VERSION ""

NS_ :

BS_:

BU_: K182_PACM K43_PSCM K17_EBCM NEO K124_ASCM XXX

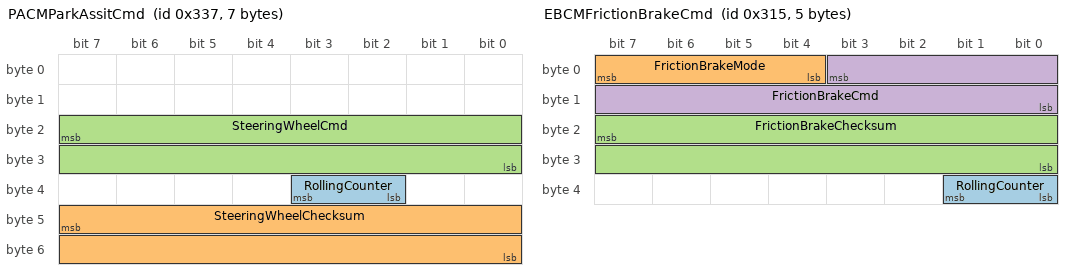
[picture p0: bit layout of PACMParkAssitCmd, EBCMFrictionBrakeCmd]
BO_ 823 PACMParkAssitCmd: 7 NEO
 SG_ RollingCounter : 35|2@0+ (1,0) [0|0] "" NEO
 SG_ SteeringWheelChecksum : 47|16@0+ (1,0) [0|0] "" NEO
 SG_ SteeringWheelCmd : 23|16@0+ (1,0) [0|0] "" NEO

BO_ 560 EBCMRegen: 6 K17_EBCM
 SG_ Regen : 1|10@0+ (1,0) [0|0] "" NEO

BO_ 368 EBCMFrictionBrakeStatus: 8 K17_EBCM
 SG_ FrictionBrakePressure : 23|16@0+ (1,0) [0|0] "" NEO
 SG_ NEW_SIGNAL_1 : 35|12@0- (1,0) [0|1] "" XXX

BO_ 789 EBCMFrictionBrakeCmd: 5 K17_EBCM
 SG_ RollingCounter : 33|2@0+ (1,0) [0|0] "" NEO
 SG_ FrictionBrakeMode : 7|4@0+ (1,0) [0|0] "" NEO
 SG_ FrictionBrakeChecksum : 23|16@0+ (1,0) [0|0] "" NEO
 SG_ FrictionBrakeCmd : 3|12@0- (1,0) [0|0] "" NEO

BO_ 192 NEW_MSG_1: 8 XXX
 SG_ NEW_SIGNAL_1 : 15|18@0- (1,0) [0|1] "" XXX

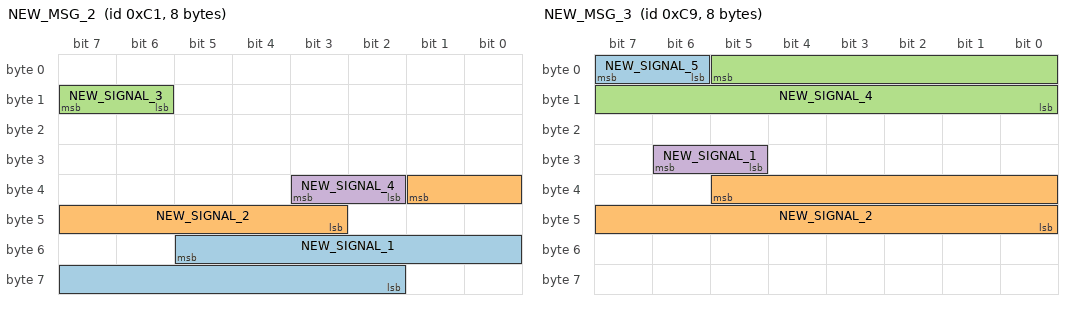
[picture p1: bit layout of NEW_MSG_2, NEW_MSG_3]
BO_ 193 NEW_MSG_2: 8 XXX
 SG_ NEW_SIGNAL_1 : 53|12@0+ (1,0) [0|1] "" XXX
 SG_ NEW_SIGNAL_2 : 33|7@0+ (1,0) [0|1] "" XXX
 SG_ NEW_SIGNAL_3 : 15|2@0+ (1,0) [0|7] "" XXX
 SG_ NEW_SIGNAL_4 : 35|2@0- (1,0) [0|1] "" XXX

BO_ 201 NEW_MSG_3: 8 XXX
 SG_ NEW_SIGNAL_5 : 7|2@0+ (1,0) [0|1] "" XXX
 SG_ NEW_SIGNAL_2 : 37|14@0+ (0.01,0) [0|16383] "" XXX
 SG_ NEW_SIGNAL_4 : 5|14@0+ (1,0) [0|1] "" XXX
 SG_ NEW_SIGNAL_1 : 30|2@0+ (1,0) [0|1] "" XXX

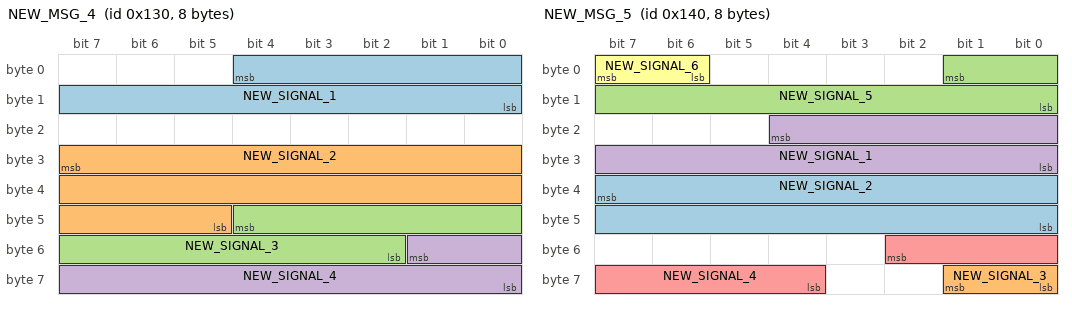
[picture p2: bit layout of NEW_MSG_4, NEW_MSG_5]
BO_ 304 NEW_MSG_4: 8 XXX
 SG_ NEW_SIGNAL_1 : 4|13@0- (1,0) [0|1] "" XXX
 SG_ NEW_SIGNAL_2 : 31|19@0- (1,0) [0|1] "" XXX
 SG_ NEW_SIGNAL_3 : 44|11@0- (1,0) [0|1] "" XXX
 SG_ NEW_SIGNAL_4 : 49|10@0- (1,0) [0|1] "" XXX

BO_ 320 NEW_MSG_5: 8 XXX
 SG_ NEW_SIGNAL_2 : 39|16@0+ (1,0) [0|1] "" XXX
 SG_ NEW_SIGNAL_3 : 57|2@0+ (1,0) [0|1] "" XXX
 SG_ NEW_SIGNAL_5 : 1|10@0- (1,0) [0|1] "" XXX
 SG_ NEW_SIGNAL_1 : 20|13@0- (1,0) [0|31] "" XXX
 SG_ NEW_SIGNAL_4 : 50|7@0+ (1,0) [0|1] "" XXX
 SG_ NEW_SIGNAL_6 : 7|2@0+ (1,0) [0|1] "" XXX

BO_ 460 NEW_MSG_6: 8 XXX
 SG_ NEW_SIGNAL_1 : 14|7@0+ (1,0) [0|1] "" XXX

BO_ 462 NEW_MSG_7: 8 XXX
 SG_ NEW_SIGNAL_1 : 4|2@0+ (1,0) [0|1] "" XXX

BO_ 381 NEW_MSG_8: 8 XXX
 SG_ NEW_SIGNAL_1 : 3|12@0- (1,0) [0|1] "" XXX

BO_ 458 NEW_MSG_9: 8 XXX
 SG_ NEW_SIGNAL_1 : 48|9@0+ (1,0) [0|1] "" XXX
 SG_ NEW_SIGNAL_2 : 2|11@0- (1,0) [0|1] "" XXX

BO_ 568 NEW_MSG_10: 8 XXX
 SG_ NEW_SIGNAL_1 : 9|2@0+ (1,0) [0|1] "" XXX

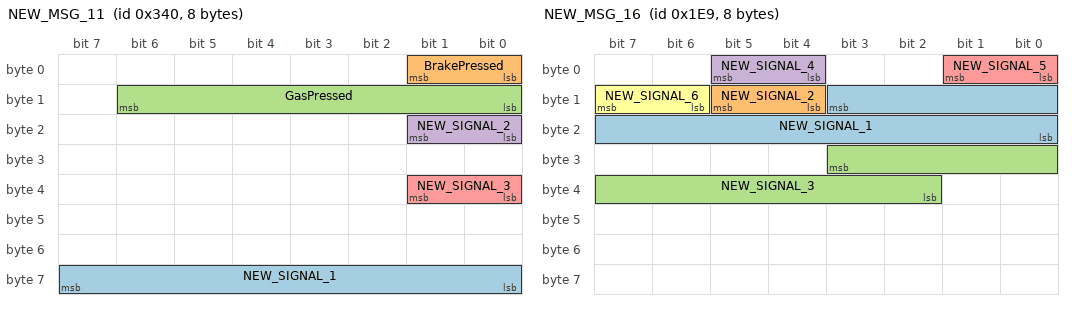
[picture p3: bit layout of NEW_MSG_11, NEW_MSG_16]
BO_ 832 NEW_MSG_11: 8 XXX
 SG_ NEW_SIGNAL_1 : 63|8@0- (1,0) [0|1] "" XXX
 SG_ BrakePressed : 1|2@0+ (1,0) [0|1] "" XXX
 SG_ GasPressed : 14|7@0+ (1,0) [0|1] "" XXX
 SG_ NEW_SIGNAL_2 : 17|2@0+ (1,0) [0|1] "" XXX
 SG_ NEW_SIGNAL_3 : 33|2@0+ (1,0) [0|1] "" XXX

BO_ 1001 NEW_MSG_12: 8 XXX
 SG_ NEW_SIGNAL_1 : 11|12@0+ (1,0) [0|1] "" XXX
 SG_ NEW_SIGNAL_2 : 27|12@0+ (1,0) [0|1] "" XXX

BO_ 1003 NEW_MSG_13: 8 XXX
 SG_ NEW_SIGNAL_1 : 22|7@0+ (1,0) [0|1] "" XXX

BO_ 197 NEW_MSG_14: 8 XXX

BO_ 384 NEW_MSG_15: 8 XXX

BO_ 489 NEW_MSG_16: 8 XXX
 SG_ NEW_SIGNAL_1 : 11|12@0- (1,0) [0|1] "" XXX
 SG_ NEW_SIGNAL_2 : 13|2@0- (1,0) [0|1] "" XXX
 SG_ NEW_SIGNAL_3 : 27|10@0- (1,0) [0|1] "" XXX
 SG_ NEW_SIGNAL_4 : 5|2@0+ (1,0) [0|1] "" XXX
 SG_ NEW_SIGNAL_5 : 1|2@0+ (1,0) [0|1] "" XXX
 SG_ NEW_SIGNAL_6 : 15|2@0+ (1,0) [0|1] "" XXX

BO_ 508 NEW_MSG_17: 8 XXX
 SG_ NEW_SIGNAL_1 : 48|13@0+ (1,0) [0|1] "" XXX
 SG_ NEW_SIGNAL_3 : 7|16@0- (1,0) [0|1] "" XXX
 SG_ NEW_SIGNAL_4 : 39|16@0+ (1,0) [0|1] "" XXX
 SG_ NEW_SIGNAL_2 : 23|16@0- (1,0) [0|1] "" XXX

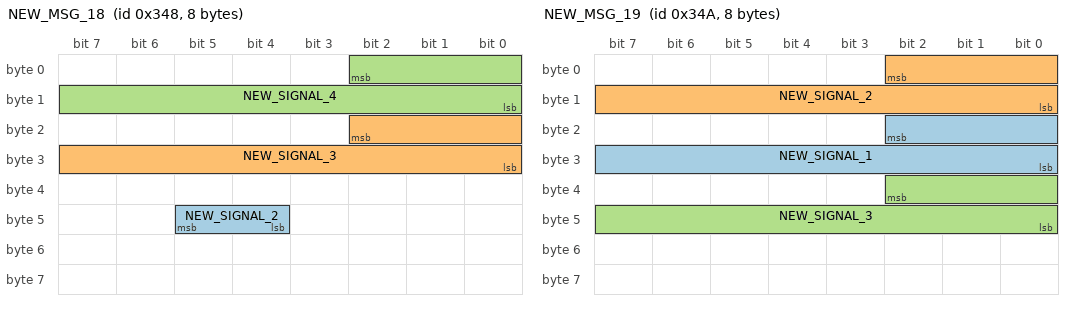
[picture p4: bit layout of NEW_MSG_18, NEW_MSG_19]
BO_ 840 NEW_MSG_18: 8 XXX
 SG_ NEW_SIGNAL_2 : 45|2@0+ (1,0) [0|1] "" XXX
 SG_ NEW_SIGNAL_3 : 18|11@0+ (1,0) [0|1] "" XXX
 SG_ NEW_SIGNAL_4 : 2|11@0+ (1,0) [0|1] "" XXX

BO_ 842 NEW_MSG_19: 8 XXX
 SG_ NEW_SIGNAL_1 : 18|11@0+ (1,0) [0|1] "" XXX
 SG_ NEW_SIGNAL_2 : 2|11@0+ (1,0) [0|1] "" XXX
 SG_ NEW_SIGNAL_3 : 34|11@0+ (1,0) [0|1] "" XXX

BO_ 386 NEW_MSG_20: 8 XXX
 SG_ NEW_SIGNAL_2 : 14|2@0+ (1,0) [0|1] "" XXX
 SG_ NEW_SIGNAL_1 : 9|10@0- (1,0) [0|1] "" XXX

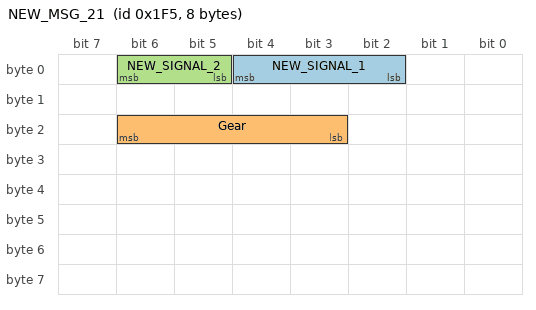
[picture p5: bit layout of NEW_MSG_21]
BO_ 501 NEW_MSG_21: 8 XXX
 SG_ NEW_SIGNAL_1 : 4|3@0+ (1,0) [0|1] "" XXX
 SG_ Gear : 22|4@0+ (1,0) [0|1] "" XXX
 SG_ NEW_SIGNAL_2 : 6|2@0+ (1,0) [0|1] "" XXX

BO_ 554 NEW_MSG_22: 8 XXX

BO_ 564 NEW_MSG_23: 8 XXX
 SG_ NEW_SIGNAL_1 : 23|8@0+ (1,0) [0|1] "" XXX
 SG_ NEW_SIGNAL_2 : 31|2@0+ (1,0) [0|1] "" XXX

BO_ 512 NEW_MSG_24: 8 XXX

BO_TX_BU_ 823 : K43_PSCM,NEO;
BO_TX_BU_ 789 : NEO,K17_EBCM;

CM_ BU_ K182_PACM "Parking Assist Control Module";
CM_ BU_ K43_PSCM "Power Steering Control Module";
CM_ BU_ K17_EBCM "Electronic Brake Control Module";
CM_ BU_ NEO "Comma NEO";
CM_ BU_ K124_ASCM "Active Safety Control Module";
